VERSION ""

NS_ :

BS_:

BU_: BRIDGE MASTER GEO MOTOR SENSOR

BO_ 768 GEO_HEARTBEAT: 1 GEO
 SG_ GEO_HEARTBEAT_cmd : 0|8@1+ (1,0) [0|0] "" MASTER

BO_ 256 SENSOR_HEARTBEAT: 1 SENSOR
 SG_ SENSOR_HEARTBEAT_cmd : 0|8@1+ (1,0) [0|0] "" MASTER

BO_ 1024 BRIDGE_HEARTBEAT: 1 BRIDGE
 SG_ BRIDGE_HEARTBEAT_cmd : 0|8@1+ (1,0) [0|0] "" MASTER

BO_ 512 MOTOR_HEARTBEAT: 1 MOTOR
 SG_ MOTOR_HEARTBEAT_cmd : 0|8@1+ (1,0) [0|0] "" MASTER

BO_ 0 MASTER_HEARTBEAT: 1 MASTER
 SG_ MASTER_HEARTBEAT_cmd : 0|8@1+ (1,0) [0|0] "" MOTOR

BO_ 2 MASTER_DEBUG: 4 MASTER
 SG_ MASTER_DEBUG_navigation_state_enum : 0|8@1+ (1,0) [0|0] "" MOTOR
 SG_ MASTER_DEBUG_navigation_go : 8|1@1+ (1,0) [0|0] "" MOTOR

BO_ 770 GEO_COORDINATE_DATA: 8 GEO
 SG_ GEO_DATA_Latitude : 0|32@1+ (0.00000001,0) [0|0] "" MASTER,BRIDGE
 SG_ GEO_DATA_Longitude : 32|32@1+ (0.0000001,-150) [0|0] "" MASTER,BRIDGE

BO_ 771 GEO_DEBUG_DATA: 8 GEO
 SG_ GEO_COMPASS_Calibration : 0|8@1+ (1,0) [0|0] "" MASTER,BRIDGE
 SG_ GEO_COMPASS_Heading : 8|32@1+ (0.1,0) [0|0] "" MASTER,BRIDGE

BO_ 769 GEO_DATA: 8 GEO
 SG_ GEO_DATA_Distance : 0|32@1+ (0.01,0) [0|0] "" MASTER,BRIDGE
 SG_ GEO_DATA_Angle : 32|32@1+ (0.1,-180) [0|0] "" MASTER,BRIDGE

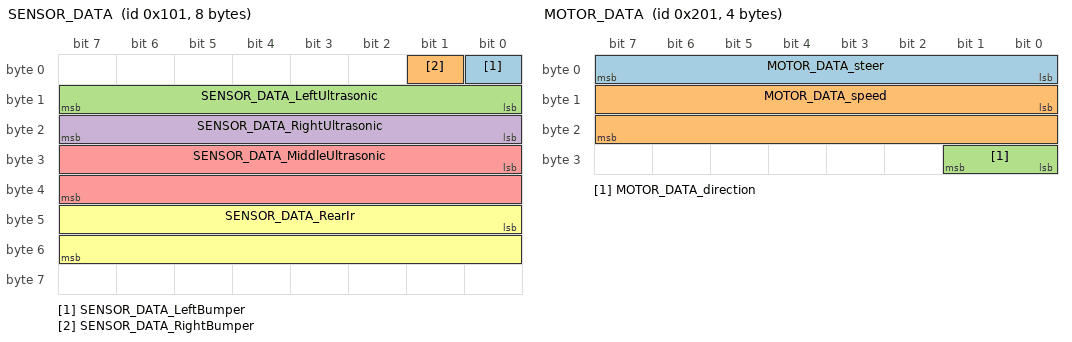
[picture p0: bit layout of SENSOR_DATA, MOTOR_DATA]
BO_ 257 SENSOR_DATA: 8 SENSOR
 SG_ SENSOR_DATA_LeftBumper : 0|1@1+ (1,0) [0|0] "" MASTER,BRIDGE
 SG_ SENSOR_DATA_RightBumper : 1|1@1+ (1,0) [0|0] "" MASTER,BRIDGE
 SG_ SENSOR_DATA_LeftUltrasonic : 8|8@1+ (1,0) [0|0] "" MASTER,BRIDGE
 SG_ SENSOR_DATA_RightUltrasonic : 16|8@1+ (1,0) [0|0] "" MASTER,BRIDGE
 SG_ SENSOR_DATA_MiddleUltrasonic : 24|16@1+ (1,0) [0|0] "" MASTER,BRIDGE
 SG_ SENSOR_DATA_RearIr : 40|16@1+ (1,0) [0|0] "" MASTER

BO_ 1025 BRIDGE_DATA_CMD: 1 BRIDGE
 SG_ BRIDGE_DATA_CMD_start_stop : 0|1@1+ (1,0) [0|1] "" MASTER

BO_ 1026 BRIDGE_CHECKPOINT: 8 BRIDGE
 SG_ BRIDGE_DATA_Latitude : 0|32@1+ (0.00000001,0) [0|0] "" MASTER,GEO
 SG_ BRIDGE_DATA_Longitude : 32|32@1+ (0.0000001,-150) [0|0] "" MASTER,GEO

BO_ 513 MOTOR_DATA: 4 MOTOR
 SG_ MOTOR_DATA_steer : 0|8@1- (1,0) [0|0] "" MASTER,BRIDGE
 SG_ MOTOR_DATA_speed : 8|16@1+ (0.1,0) [0|0] "MPS" MASTER,BRIDGE
 SG_ MOTOR_DATA_direction : 24|2@1+ (1,0) [0|0] "" MASTER,BRIDGE

BO_ 514 MOTOR_DEBUG_RPM_PARTIAL: 4 MOTOR
 SG_ MOTOR_DEBUG_rpm_part : 0|32@1- (1,0) [0|0] "RPM" MASTER,BRIDGE,DEBUG

BO_ 515 MOTOR_DEBUG_RPM_ACTUAL: 4 MOTOR
 SG_ MOTOR_DEBUG_rpm_act : 0|32@1- (0.01,0) [0|0] "RPM" MASTER,BRIDGE,DEBUG

BO_ 516 MOTOR_DEBUG_PI_ERROR: 4 MOTOR
 SG_ MOTOR_DEBUG_pi_err : 0|32@1- (0.01,0) [0|0] "MPS" MASTER,BRIDGE,DEBUG

BO_ 517 MOTOR_DEBUG_LARGE_ERROR_CNT: 4 MOTOR
 SG_ MOTOR_DEBUG_lg_err_cnt : 0|32@1+ (1,0) [0|0] "" MASTER,BRIDGE,DEBUG

BO_ 518 MOTOR_DEBUG_PROPORTIONAL_CMD: 4 MOTOR
 SG_ MOTOR_DEBUG_prop_cmd : 0|32@1- (0.01,0) [0|0] "" MASTER,BRIDGE,DEBUG

BO_ 519 MOTOR_DEBUG_INTEGRAL_CMD: 4 MOTOR
 SG_ MOTOR_DEBUG_int_cmd : 0|32@1- (0.01,0) [0|0] "" MASTER,BRIDGE,DEBUG

BO_ 520 MOTOR_DEBUG_INTEGRAL_CMD_OLD: 4 MOTOR
 SG_ MOTOR_DEBUG_int_cmd_old : 0|32@1- (0.01,0) [0|0] "" MASTER,BRIDGE,DEBUG

BO_ 521 MOTOR_DEBUG_OUTPUT: 4 MOTOR
 SG_ MOTOR_DEBUG_out : 0|32@1- (0.01,0) [0|0] "Percent" MASTER,BRIDGE,DEBUG

BO_ 522 MOTOR_DEBUG_PWM_ACTUAL: 4 MOTOR
 SG_ MOTOR_DEBUG_pwm_act : 0|32@1- (0.01,0) [0|0] "PWM Pulse Width" MASTER,BRIDGE,DEBUG

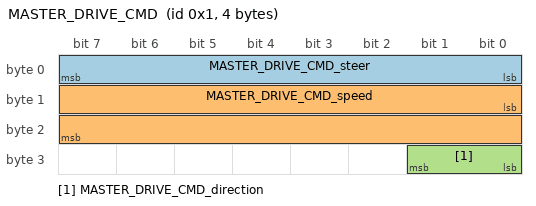
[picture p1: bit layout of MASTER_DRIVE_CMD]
BO_ 1 MASTER_DRIVE_CMD: 4 MASTER
 SG_ MASTER_DRIVE_CMD_steer : 0|8@1- (1,0) [0|0] "" MOTOR
 SG_ MASTER_DRIVE_CMD_speed : 8|16@1+ (0.1,0) [0|0] "MPS" MOTOR
 SG_ MASTER_DRIVE_CMD_direction : 24|2@1+ (1,0) [0|0] "" MOTOR

BO_ 2 MASTER_DEBUG: 4 MASTER
 SG_ MASTER_DEBUG_navigation_state_enum : 0|8@1+ (1,0) [0|0] "" MOTOR
 SG_ MASTER_DEBUG_navigation_go : 8|1@1+ (1,0) [0|0] "" MOTOR

BA_ "FieldType" SG_ 2 MASTER_DEBUG_navigation_state_enum "MASTER_DEBUG_navigation_state_enum";

BA_ "FieldType" SG_ 1 MASTER_DRIVE_CMD_direction "MASTER_DRIVE_CMD_direction_E";
BA_ "FieldType" SG_ 513 MOTOR_DATA_direction "MOTOR_DATA_direction_E";

VAL_ 1 MASTER_DRIVE_CMD_direction 0 "stop_cmd" 1 "forward_cmd" 2 "backward_cmd" ;
VAL_ 2 MASTER_DEBUG_navigation_state_enum 0 "NAV_INIT" 1 "NAV_WAIT" 2 "NAV_NAVIGATE" 3 "NAV_OBSTACLE_RIGHT" 4 "NAV_OBSTACLE_LEFT" 5 "NAV_OBSTACLE_MIDDLE_FAR" 6 "NAV_OBSTACLE_MIDDLE_CLOSE" ;
VAL_ 513 MOTOR_DATA_direction 0 "stop_act" 1 "forward_act" 2 "backward_act" ;

BA_DEF_ "BusType" STRING ;
BA_DEF_ SG_ "FieldType" STRING ;

BA_DEF_DEF_ "BusType" "CAN";
BA_DEF_DEF_ "FieldType" "";
